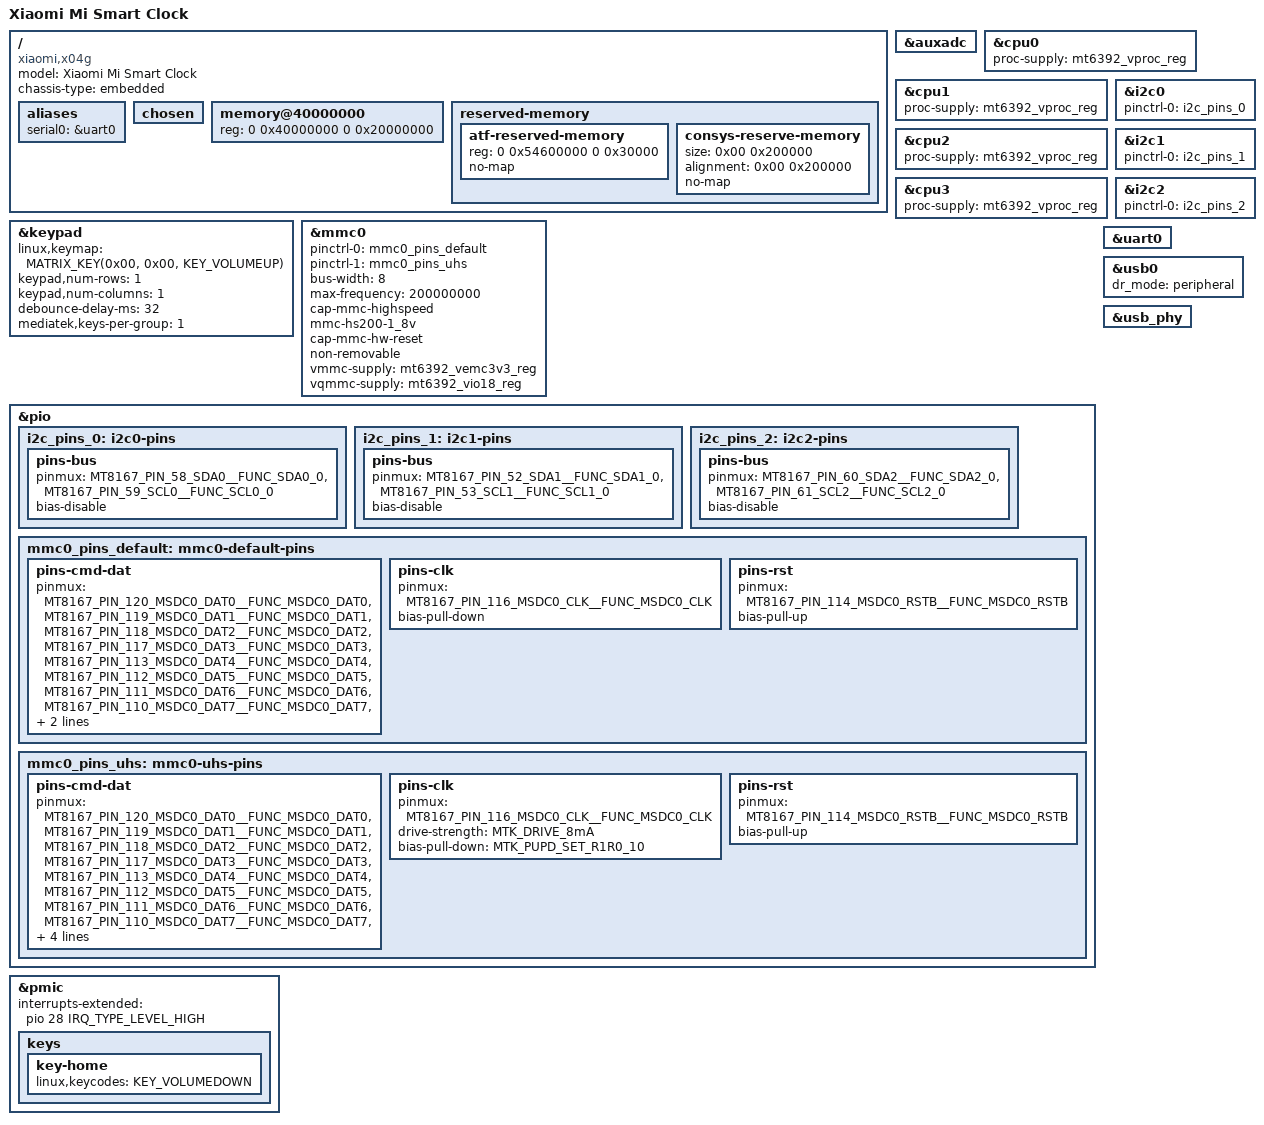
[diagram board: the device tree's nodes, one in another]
// SPDX-License-Identifier: GPL-2.0
/*
 * Copyright (c) 2025 FIXME
 */
/dts-v1/;
#include <dt-bindings/gpio/gpio.h>
#include <dt-bindings/input/linux-event-codes.h>
#include "mt8167.dtsi"
#include "mt6392.dtsi"

/ {
	model = "Xiaomi Mi Smart Clock";
	chassis-type = "embedded";
	compatible = "xiaomi,x04g", "mediatek,mt8167";

	aliases {
		serial0 = &uart0;
	};

	chosen {
		// FIXME clean up
		#address-cells = <2>;
		#size-cells = <2>;
		ranges;
	};

	//extcon_usb: extcon_iddig {
	//	compatible = "linux,extcon-usb-gpio";
	//	id-gpios = <&pio 41 GPIO_ACTIVE_HIGH>;
	//};

	memory@40000000 {
		device_type = "memory";
		reg = <0 0x40000000 0 0x20000000>;
	};

	reserved-memory {
		#address-cells = <2>;
		#size-cells = <2>;
		ranges;

		atf-reserved-memory {
			reg = <0 0x54600000 0 0x30000>;
			no-map;
		};

		consys-reserve-memory {
			size = <0x00 0x200000>;
			alignment = <0x00 0x200000>;
			no-map;
		};
	};
};

&auxadc {
	status = "okay";
};

/* With the firmware on Android devices, cores don't seem to come back after out
   idle/unplug (though initial SMP boot is fine) */

&cpu0 {
	/delete-property/ cpu-idle-states;
	proc-supply = <&mt6392_vproc_reg>;
};

&cpu1 {
	/delete-property/ cpu-idle-states;
	proc-supply = <&mt6392_vproc_reg>;
};

&cpu2 {
	/delete-property/ cpu-idle-states;
	proc-supply = <&mt6392_vproc_reg>;
};

&cpu3 {
	/delete-property/ cpu-idle-states;
	proc-supply = <&mt6392_vproc_reg>;
};

&i2c0 {
	pinctrl-names = "default";
	pinctrl-0 = <&i2c_pins_0>;
	status = "okay";

	/* alsps em3071x @ 24 */
};

&i2c1 {
	pinctrl-names = "default";
	pinctrl-0 = <&i2c_pins_1>;
	status = "okay";

	/* es7243 mi,es7243 @ 13 */
};

&i2c2 {
	pinctrl-names = "default";
	pinctrl-0 = <&i2c_pins_2>;
	status = "okay";

	/* cap_touch mediatek,cap_touch @ 38 */ /* TODO: poke running android to figure out which touch panel is actually there */
	/* cap_touch mediatek,tlsc6x_touch @ 2e */ /* <<< https://github.com/fsong549/touchpanel_driver/blob/master/tlsc6x/sc9863_tlsc6x/tlsc6x_main.c */
};

&keypad {
	status = "okay";
	linux,keymap = <MATRIX_KEY(0x00, 0x00, KEY_VOLUMEUP)>;
	keypad,num-rows = <1>;
	keypad,num-columns = <1>;
	debounce-delay-ms = <32>;
	mediatek,keys-per-group = <1>;
};

&mmc0 {
	status = "okay";

	pinctrl-names = "default", "state_uhs";
	pinctrl-0 = <&mmc0_pins_default>;
	pinctrl-1 = <&mmc0_pins_uhs>;

	bus-width = <8>;
	max-frequency = <200000000>;
	cap-mmc-highspeed;
	mmc-hs200-1_8v;
	cap-mmc-hw-reset;
	non-removable;

	vmmc-supply = <&mt6392_vemc3v3_reg>;
	vqmmc-supply = <&mt6392_vio18_reg>;
};

&pio {
	i2c_pins_0: i2c0-pins {
		pins-bus {
			pinmux = <MT8167_PIN_58_SDA0__FUNC_SDA0_0>,
				 <MT8167_PIN_59_SCL0__FUNC_SCL0_0>;
			bias-disable;
		};
	};

	i2c_pins_1: i2c1-pins {
		pins-bus {
			pinmux = <MT8167_PIN_52_SDA1__FUNC_SDA1_0>,
				 <MT8167_PIN_53_SCL1__FUNC_SCL1_0>;
			bias-disable;
		};
	};

	i2c_pins_2: i2c2-pins {
		pins-bus {
			pinmux = <MT8167_PIN_60_SDA2__FUNC_SDA2_0>,
				 <MT8167_PIN_61_SCL2__FUNC_SCL2_0>;
			bias-disable;
		};
	};

	mmc0_pins_default: mmc0-default-pins {
		pins-cmd-dat {
			pinmux = <MT8167_PIN_120_MSDC0_DAT0__FUNC_MSDC0_DAT0>,
				 <MT8167_PIN_119_MSDC0_DAT1__FUNC_MSDC0_DAT1>,
				 <MT8167_PIN_118_MSDC0_DAT2__FUNC_MSDC0_DAT2>,
				 <MT8167_PIN_117_MSDC0_DAT3__FUNC_MSDC0_DAT3>,
				 <MT8167_PIN_113_MSDC0_DAT4__FUNC_MSDC0_DAT4>,
				 <MT8167_PIN_112_MSDC0_DAT5__FUNC_MSDC0_DAT5>,
				 <MT8167_PIN_111_MSDC0_DAT6__FUNC_MSDC0_DAT6>,
				 <MT8167_PIN_110_MSDC0_DAT7__FUNC_MSDC0_DAT7>,
				 <MT8167_PIN_115_MSDC0_CMD__FUNC_MSDC0_CMD>;
			bias-pull-up;
		};

		pins-clk {
			pinmux = <MT8167_PIN_116_MSDC0_CLK__FUNC_MSDC0_CLK>;
			bias-pull-down;
		};

		pins-rst {
			pinmux = <MT8167_PIN_114_MSDC0_RSTB__FUNC_MSDC0_RSTB>;
			bias-pull-up;
		};
	};

	mmc0_pins_uhs: mmc0-uhs-pins {
		pins-cmd-dat {
			pinmux = <MT8167_PIN_120_MSDC0_DAT0__FUNC_MSDC0_DAT0>,
				 <MT8167_PIN_119_MSDC0_DAT1__FUNC_MSDC0_DAT1>,
				 <MT8167_PIN_118_MSDC0_DAT2__FUNC_MSDC0_DAT2>,
				 <MT8167_PIN_117_MSDC0_DAT3__FUNC_MSDC0_DAT3>,
				 <MT8167_PIN_113_MSDC0_DAT4__FUNC_MSDC0_DAT4>,
				 <MT8167_PIN_112_MSDC0_DAT5__FUNC_MSDC0_DAT5>,
				 <MT8167_PIN_111_MSDC0_DAT6__FUNC_MSDC0_DAT6>,
				 <MT8167_PIN_110_MSDC0_DAT7__FUNC_MSDC0_DAT7>,
				 <MT8167_PIN_115_MSDC0_CMD__FUNC_MSDC0_CMD>;
			input-enable;
			drive-strength = <MTK_DRIVE_6mA>;
			bias-pull-up = <MTK_PUPD_SET_R1R0_01>;
		};

		pins-clk {
			pinmux = <MT8167_PIN_116_MSDC0_CLK__FUNC_MSDC0_CLK>;
			drive-strength = <MTK_DRIVE_8mA>;
			bias-pull-down = <MTK_PUPD_SET_R1R0_10>;
		};

		pins-rst {
			pinmux = <MT8167_PIN_114_MSDC0_RSTB__FUNC_MSDC0_RSTB>;
			bias-pull-up;
		};
	};
};

&pmic {
	interrupts-extended = <&pio 28 IRQ_TYPE_LEVEL_HIGH>;

	keys {
		key-home {
			linux,keycodes = <KEY_VOLUMEDOWN>;
		};
	};
};

&uart0 {
	status = "okay";
};

&usb0 {
	status = "okay";
	dr_mode = "peripheral";
	//maximum-speed = "high-speed";

	//vusb33-supply = <&mt6392_vusb_reg>;

	//usb_con: connector {
	//	compatible = "usb-b-connector";
	//	type = "micro";
	//};
};

&usb_phy {
	status = "okay";
};
